AUTOSAR XML (schema 00051)
package /RTE_Events_Lab
  sender receiver interface SRI_Output
    data SumResult: type=uint32
  sender receiver interface SRI_Input
    data Val1: type=uint16
    data Val2: type=uint16
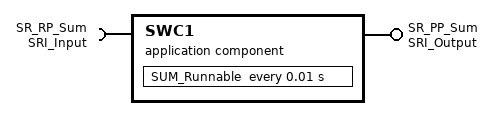
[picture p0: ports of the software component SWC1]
  application sw component type SWC1
    provide port SR_PP_Sum: provided-interface=SRI_Output
    require port SR_RP_Sum: required-interface=SRI_Input
    behavior SWC1_Behavior
      exclusive area EXCArea1
      timing event TE_10ms: start-on-event=SUM_Runnable, period=0.01
      init event InitEvent: start-on-event=SUM_Runnable
      data received event DRCEvent: start-on-event=SUM_Runnable, data=Val1
      data write completed event DWCEvent: start-on-event=SUM_Runnable, event-source=SumResult_Data
      runnable SUM_Runnable: symbol=SUM
        data-read-access:
          access Val1_Data: accessed-variable=SR_RP_Sum.Val1
          access Val2_Data: accessed-variable=SR_RP_Sum.Val2
        data-write-access:
          access SumResult_Data: accessed-variable=SR_PP_Sum.SumResult
